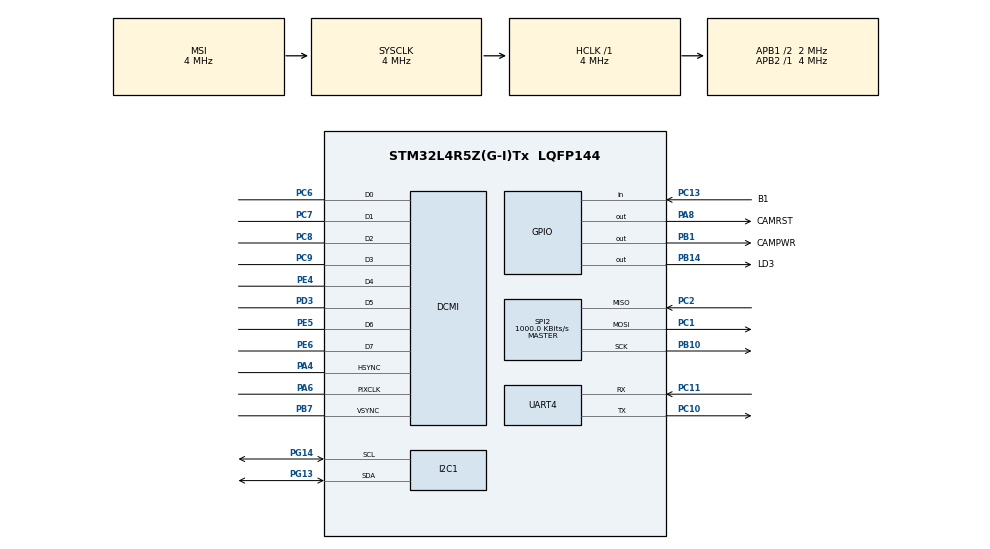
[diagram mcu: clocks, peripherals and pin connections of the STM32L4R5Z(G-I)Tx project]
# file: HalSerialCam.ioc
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Dma.DCMI.0.Direction=DMA_PERIPH_TO_MEMORY
Dma.DCMI.0.EventEnable=DISABLE
Dma.DCMI.0.Instance=DMA1_Channel1
Dma.DCMI.0.MemDataAlignment=DMA_MDATAALIGN_BYTE
Dma.DCMI.0.MemInc=DMA_MINC_ENABLE
Dma.DCMI.0.Mode=DMA_NORMAL
Dma.DCMI.0.PeriphDataAlignment=DMA_PDATAALIGN_WORD
Dma.DCMI.0.PeriphInc=DMA_PINC_DISABLE
Dma.DCMI.0.Polarity=HAL_DMAMUX_REQUEST_GEN_RISING
Dma.DCMI.0.Priority=DMA_PRIORITY_LOW
Dma.DCMI.0.RequestNumber=1
Dma.DCMI.0.SignalID=NONE
Dma.DCMI.0.SyncEnable=DISABLE
Dma.DCMI.0.SyncPolarity=HAL_DMAMUX_SYNC_NO_EVENT
Dma.DCMI.0.SyncRequestNumber=1
Dma.DCMI.0.SyncSignalID=NONE
Dma.Request0=DCMI
I2C1.Speed=100
I2C1.Timing=0x00000509
Mcu.Family=STM32L4
Mcu.Name=STM32L4R5Z(G-I)Tx
Mcu.Package=LQFP144
NVIC.DMA1_Channel1_IRQn=true\:0\:0\:false\:false\:true\:false\:true
NVIC.PriorityGroup=NVIC_PRIORITYGROUP_4
PA13\ (JTMS/SWDIO).Mode=Serial_Wire
PA13\ (JTMS/SWDIO).Signal=SYS_JTMS-SWDIO
PA14\ (JTCK/SWCLK).Mode=Serial_Wire
PA14\ (JTCK/SWCLK).Signal=SYS_JTCK-SWCLK
PA4.Mode=Slave_8_bits_External_Synchro
PA4.Signal=DCMI_HSYNC
PA6.Mode=Slave_8_bits_External_Synchro
PA6.Signal=DCMI_PIXCLK
PA8.GPIO_Label=CAMRST
PA8.Signal=GPIO_Output
PB1.GPIO_Label=CAMPWR
PB1.Signal=GPIO_Output
PB10.Mode=Full_Duplex_Master
PB10.Signal=SPI2_SCK
PB14.GPIO_Label=LD3
PB14.Signal=GPIO_Output
PB7.Mode=Slave_8_bits_External_Synchro
PB7.Signal=DCMI_VSYNC
PC1.Mode=Full_Duplex_Master
PC1.Signal=SPI2_MOSI
PC10.Mode=Asynchronous
PC10.Signal=UART4_TX
PC11.Mode=Asynchronous
PC11.Signal=UART4_RX
PC13.GPIO_Label=B1
PC13.Signal=GPIO_Input
PC2.Mode=Full_Duplex_Master
PC2.Signal=SPI2_MISO
PC6.Mode=Slave_8_bits_External_Synchro
PC6.Signal=DCMI_D0
PC7.Mode=Slave_8_bits_External_Synchro
PC7.Signal=DCMI_D1
PC8.Mode=Slave_8_bits_External_Synchro
PC8.Signal=DCMI_D2
PC9.Mode=Slave_8_bits_External_Synchro
PC9.Signal=DCMI_D3
PD3.Mode=Slave_8_bits_External_Synchro
PD3.Signal=DCMI_D5
PE4.Mode=Slave_8_bits_External_Synchro
PE4.Signal=DCMI_D4
PE5.Mode=Slave_8_bits_External_Synchro
PE5.Signal=DCMI_D6
PE6.Mode=Slave_8_bits_External_Synchro
PE6.Signal=DCMI_D7
PG13.Mode=I2C
PG13.Signal=I2C1_SDA
PG14.Mode=I2C
PG14.Signal=I2C1_SCL
ProjectManager.HeapSize=0x200
ProjectManager.StackSize=0x400
ProjectManager.TargetToolchain=STM32CubeIDE
RCC.48MHZClocksFreq_Value=24000000
RCC.AHBFreq_Value=4000000
RCC.APB1CLKDivider=RCC_HCLK_DIV2
RCC.APB1Freq_Value=2000000
RCC.APB1TimFreq_Value=4000000
RCC.APB2Freq_Value=4000000
RCC.APB2TimFreq_Value=4000000
RCC.CortexFreq_Value=4000000
RCC.HCLKFreq_Value=4000000
RCC.HSE_VALUE=8000000
RCC.HSI48_VALUE=48000000
RCC.HSI_VALUE=16000000
RCC.LSE_VALUE=32768
RCC.MSI_VALUE=4000000
RCC.PLLMUL=RCC_PLL_MUL9
RCC.PRESCALERUSB=RCC_USBCLKSOURCE_PLL_DIV1_5
RCC.SYSCLKFreq_VALUE=4000000
RCC.SYSCLKSourceVirtual=RCC_SYSCLKSOURCE_PLLCLK
RCC.USBFreq_Value=16000000
RCC.VCOOutputFreq_Value=32000000
SPI2.CalculateBaudRate=1000.0 KBits/s
SPI2.Direction=SPI_DIRECTION_2LINES
SPI2.Mode=SPI_MODE_MASTER
SPI2.VirtualType=VM_MASTER
board=NUCLEO-L4R5ZI

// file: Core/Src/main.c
/* USER CODE BEGIN Header */
/**
  ******************************************************************************
  * @file           : main.c
  * @brief          : Main program body
  ******************************************************************************
  * @attention
  *
  * Copyright (c) 2022 STMicroelectronics.
  * All rights reserved.
  *
  * This software is licensed under terms that can be found in the LICENSE file
  * in the root directory of this software component.
  * If no LICENSE file comes with this software, it is provided AS-IS.
  *
  ******************************************************************************
  */
/* USER CODE END Header */
#include "main.h"
#include "dcmi.h"
#include "dma.h"
#include "i2c.h"
#include "spi.h"
#include "usart.h"
#include "gpio.h"

/* USER CODE BEGIN Includes */
#include "ov5640.h"

#include "test.h"
/* USER CODE END Includes */

void SystemClock_Config(void);

int main(void)
{

  /* MCU Configuration--------------------------------------------------------*/

  /* Reset of all peripherals, Initializes the Flash interface and the Systick. */
  HAL_Init();

  /* Configure the system clock */
  SystemClock_Config();

  /* Initialize all configured peripherals */
  MX_GPIO_Init();
  MX_DCMI_Init();
  MX_DMA_Init();
  MX_UART4_Init();
  MX_SPI2_Init();
  MX_I2C1_Init();
  /* USER CODE BEGIN 2 */
  // camera connection test
  Test_OV5640();

  /* USER CODE END 2 */

  /* Infinite loop */
  while (1)
  {

  }
}

void SystemClock_Config(void)
{
  RCC_OscInitTypeDef RCC_OscInitStruct = {0};
  RCC_ClkInitTypeDef RCC_ClkInitStruct = {0};

  /** Configure the main internal regulator output voltage
  */
  if (HAL_PWREx_ControlVoltageScaling(PWR_REGULATOR_VOLTAGE_SCALE1) != HAL_OK)
  {
    Error_Handler();
  }
  /** Initializes the RCC Oscillators according to the specified parameters
  * in the RCC_OscInitTypeDef structure.
  */
  RCC_OscInitStruct.OscillatorType = RCC_OSCILLATORTYPE_MSI;
  RCC_OscInitStruct.MSIState = RCC_MSI_ON;
  RCC_OscInitStruct.MSICalibrationValue = 0;
  RCC_OscInitStruct.MSIClockRange = RCC_MSIRANGE_6;
  RCC_OscInitStruct.PLL.PLLState = RCC_PLL_NONE;
  if (HAL_RCC_OscConfig(&RCC_OscInitStruct) != HAL_OK)
  {
    Error_Handler();
  }
  /** Initializes the CPU, AHB and APB buses clocks
  */
  RCC_ClkInitStruct.ClockType = RCC_CLOCKTYPE_HCLK|RCC_CLOCKTYPE_SYSCLK
                              |RCC_CLOCKTYPE_PCLK1|RCC_CLOCKTYPE_PCLK2;
  RCC_ClkInitStruct.SYSCLKSource = RCC_SYSCLKSOURCE_MSI;
  RCC_ClkInitStruct.AHBCLKDivider = RCC_SYSCLK_DIV1;
  RCC_ClkInitStruct.APB1CLKDivider = RCC_HCLK_DIV2;
  RCC_ClkInitStruct.APB2CLKDivider = RCC_HCLK_DIV1;

  if (HAL_RCC_ClockConfig(&RCC_ClkInitStruct, FLASH_LATENCY_0) != HAL_OK)
  {
    Error_Handler();
  }
}

void Error_Handler(void)
{
  __disable_irq();
  while (1)
  {
  }
}
